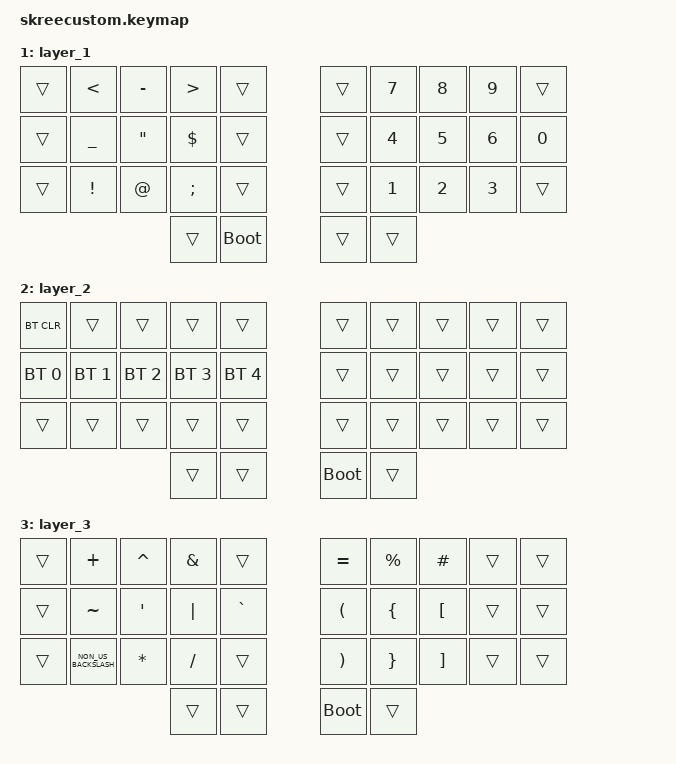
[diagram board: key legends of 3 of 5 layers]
/*
 * Copyright (c) 2020 The ZMK Contributors
 *
 * SPDX-License-Identifier: MIT
 */
//#include <behaviors/mouse_keys.dtsi>

#include <behaviors.dtsi>
#include <dt-bindings/zmk/bt.h>
#include <dt-bindings/zmk/keys.h>

/ {
    keymap {
        compatible = "zmk,keymap";

        default_layer {
            bindings = <
&kp Q           &kp W        &kp F          &kp P         &kp B             &kp Y    &kp L           &kp U        &kp Y        &kp COLON
&mt LEFT_ALT A  &mt LCTRL R  &mt LGUI S     &kp T         &kp G             &kp M    &kp N           &mt RGUI E   &mt RCTRL I  &mt RALT O
&kp Z           &kp X        &kp C          &kp D         &kp V             &kp K    &kp H           &kp COMMA    &kp DOT      &kp QUESTION
                             &kp BACKSPACE  &lt 4 ESC     &sk LEFT_SHIFT    &kp TAB  &lt 3 ENTER     &lt 1 SPACE
                                            &kp CAPSLOCK                             &lt 2 CAPSLOCK
            >;
        };

        layer_1 {
            bindings = <
&trans  &kp LESS_THAN    &kp MINUS          &kp GREATER_THAN  &trans    &trans  &kp NUMBER_7  &kp NUMBER_8  &kp NUMBER_9  &trans
&trans  &kp UNDERSCORE   &kp DOUBLE_QUOTES  &kp DOLLAR        &trans    &trans  &kp NUMBER_4  &kp NUMBER_5  &kp NUMBER_6  &kp NUMBER_0
&trans  &kp EXCLAMATION  &kp AT_SIGN        &kp SEMICOLON     &trans    &trans  &kp NUMBER_1  &kp NUMBER_2  &kp NUMBER_3  &trans
                         &trans             &bootloader       &trans    &trans
            >;
        };

        layer_2 {
            bindings = <
&bt BT_CLR    &trans        &trans        &trans        &trans          &trans  &trans  &trans  &trans  &trans
&bt BT_SEL 0  &bt BT_SEL 1  &bt BT_SEL 2  &bt BT_SEL 3  &bt BT_SEL 4    &trans  &trans  &trans  &trans  &trans
&trans        &trans        &trans        &trans        &trans          &trans  &trans  &trans  &trans  &trans
                            &trans        &trans        &bootloader     &trans
            >;
        };

        layer_3 {
            bindings = <
&trans  &kp PLUS              &kp CARET         &kp AMPERSAND  &trans         &kp EQUAL              &kp PERCENT      &kp HASH           &trans  &trans
&trans  &kp TILDE             &kp SINGLE_QUOTE  &kp PIPE       &kp GRAVE      &kp LEFT_PARENTHESIS   &kp LEFT_BRACE   &kp LEFT_BRACKET   &trans  &trans
&trans  &kp NON_US_BACKSLASH  &kp ASTERISK      &kp SLASH      &trans         &kp RIGHT_PARENTHESIS  &kp RIGHT_BRACE  &kp RIGHT_BRACKET  &trans  &trans
                              &trans            &trans         &bootloader    &trans
            >;
        };

        layer_4 {
            bindings = <
&trans  &trans  &trans  &trans  &trans    &trans  &kp HOME        &kp UP_ARROW    &kp END          &trans
&trans  &trans  &trans  &trans  &trans    &trans  &kp LEFT_ARROW  &kp DOWN_ARROW  &kp RIGHT_ARROW  &trans
&trans  &trans  &trans  &trans  &trans    &trans  &trans          &trans          &trans           &trans
                &trans  &trans  &trans    &trans  &trans          &trans
                        &trans                    &trans
            >;
        };
    };
};
